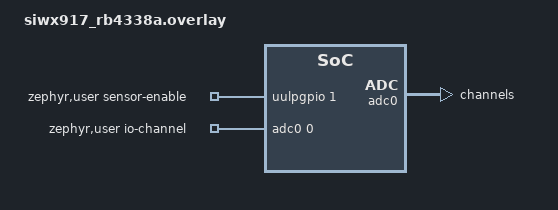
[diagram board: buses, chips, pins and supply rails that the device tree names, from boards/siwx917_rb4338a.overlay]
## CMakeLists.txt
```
# SPDX-License-Identifier: Apache-2.0

cmake_minimum_required(VERSION 3.20.0)

find_package(Zephyr REQUIRED HINTS $ENV{ZEPHYR_BASE})
project(ghanode)

target_sources(app PRIVATE
  src/main.c
  src/sensors.c
  src/wifi.c
  src/mqtt_link.c
  src/reading.c
  src/payload.c
  src/lux.c
  src/recovery.c
  src/sntp_sync.c
  src/timesync.c
)

# secret.h (gitignored) lives next to this file.
target_include_directories(app PRIVATE ${CMAKE_CURRENT_SOURCE_DIR})

if(CONFIG_GHANODE_MQTT_TLS)
  set(gen_dir ${ZEPHYR_BINARY_DIR}/include/generated)
  generate_inc_file_for_target(app ${CMAKE_CURRENT_SOURCE_DIR}/certs/isrg_root_x1.pem
                               ${gen_dir}/isrg_root_x1.pem.inc)
endif()
```

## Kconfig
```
# SPDX-License-Identifier: Apache-2.0

mainmenu "ghanode SiWx917 sensor node"

menu "ghanode"

config GHANODE_MQTT_TLS
	bool "MQTT over TLS"
	default y
	depends on MQTT_LIB_TLS
	help
	  The broker must present a certificate for SECRET_MQTT_TLS_HOSTNAME
	  that chains to ISRG Root X1 (certs/isrg_root_x1.pem). The node does
	  not keep a wall clock for mbed TLS, so certificate dates are not
	  checked. Disable for plain MQTT.

config GHANODE_MQTT_BROKER_PORT
	int "MQTT broker port"
	default 8883 if GHANODE_MQTT_TLS
	default 1883

config GHANODE_MQTT_TOPIC
	string "MQTT topic readings are published to"
	default "ghanode/sensor"

config GHANODE_SAMPLE_INTERVAL_MS
	int "Sample period in milliseconds"
	default 20000

config GHANODE_READING_QUEUE_LEN
	int "Readings kept while the broker cannot be reached"
	range 1 1024
	default 30
	help
	  Bridges short outages such as a Wi-Fi handover. 30 readings at the
	  default 20 s period cover ten minutes, the same as the recovery
	  ladder's grace period before an MCU reset, which empties the queue.
	  When the queue is full the oldest reading is dropped.

config GHANODE_SNTP_RESYNC_S
	int "Seconds between SNTP queries once synced"
	default 3600

config GHANODE_SNTP_RETRY_S
	int "Seconds before retrying a failed SNTP query"
	default 60

config GHANODE_WIFI_COUNTRY
	string "Wi-Fi regulatory country code (ISO 3166-1 alpha-2)"
	default "DK"
	help
	  The NWP's default region is US, which only scans channels 1-11. Any
	  EU country code selects the EU region and enables channels 12 and 13.

endmenu

source "Kconfig.zephyr"
```

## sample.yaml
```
sample:
  name: ghanode
  description: SiWx917 sensor node publishing Si7021 and light readings over MQTT
common:
  tags:
    - net
    - wifi
    - mqtt
    - sensors
  harness: net
tests:
  ghanode.siwx917:
    platform_allow:
      - siwx917_rb4338a
    integration_platforms:
      - siwx917_rb4338a
```

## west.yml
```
# Workspace for CI, or for a fresh checkout:
#   west init -l ghanode_ze_si917 && west update
# An existing workspace with the same SDK can build this repo without it.

manifest:
  self:
    path: ghanode_ze_si917

  remotes:
    - name: silabs
      url-base: https://github.com/siliconlabssoftware

  projects:
    # Simplicity SDK for Zephyr; v2026.6.0 is based on Zephyr 4.4.1.
    - name: zephyr-silabs
      remote: silabs
      revision: v2026.6.0
      import: true
```

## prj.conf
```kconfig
# Networking: Zephyr's native IPv4/TCP stack on top of the SiWx91x Wi-Fi driver
CONFIG_NETWORKING=y
CONFIG_NET_IPV4=y
CONFIG_NET_IPV6=n
CONFIG_NET_TCP=y
CONFIG_NET_UDP=y
CONFIG_NET_SOCKETS=y
CONFIG_NET_DHCPV4=y
CONFIG_NET_MGMT=y
CONFIG_NET_MGMT_EVENT=y
CONFIG_NET_MGMT_EVENT_INFO=y
CONFIG_NET_HOSTNAME_ENABLE=y
CONFIG_NET_HOSTNAME_DYNAMIC=y
# A TCP connect to a host that is down fails after this; a closed port fails at once.
CONFIG_NET_SOCKETS_CONNECT_TIMEOUT=10000

CONFIG_NET_PKT_RX_COUNT=16
CONFIG_NET_PKT_TX_COUNT=16
CONFIG_NET_BUF_RX_COUNT=32
CONFIG_NET_BUF_TX_COUNT=32
CONFIG_NET_MAX_CONTEXTS=6

CONFIG_WIFI=y
CONFIG_WIFI_LOG_LEVEL_WRN=y

# SNTP timestamps; the DNS server comes from DHCP.
CONFIG_SNTP=y
CONFIG_DNS_RESOLVER=y

CONFIG_MQTT_LIB=y
CONFIG_MQTT_KEEPALIVE=60
CONFIG_MQTT_CLEAN_SESSION=y

# MQTT over TLS (CONFIG_GHANODE_MQTT_TLS): TLS 1.2 with the broker's RSA
# certificate. The broker's chain arrives in one record of up to 16 KB; the
# node only sends small ones.
CONFIG_MQTT_LIB_TLS=y
CONFIG_NET_SOCKETS_SOCKOPT_TLS=y
CONFIG_MBEDTLS=y
CONFIG_MBEDTLS_CIPHERSUITE_TLS_ECDHE_RSA_WITH_AES_128_GCM_SHA256=y
CONFIG_MBEDTLS_CIPHERSUITE_TLS_ECDHE_RSA_WITH_AES_256_GCM_SHA384=y
CONFIG_MBEDTLS_PEM_PARSE_C=y
CONFIG_MBEDTLS_SSL_SERVER_NAME_INDICATION=y
CONFIG_MBEDTLS_ENABLE_HEAP=y
CONFIG_MBEDTLS_HEAP_SIZE=65000
CONFIG_MBEDTLS_SSL_IN_CONTENT_LEN=16384
CONFIG_MBEDTLS_SSL_OUT_CONTENT_LEN=4096
# The software handshake takes about 9 s on the board, against a 10 s default.
# The p256-m driver (CONFIG_MBEDTLS_PSA_P256M_DRIVER_ENABLED) failed the ECDHE
# step with -0x7f80 here.
CONFIG_NET_SOCKETS_TLS_CONNECT_TIMEOUT=30000
# Logs the Mbed TLS error code when a handshake fails.
CONFIG_NET_LOG=y
CONFIG_NET_SOCKETS_LOG_LEVEL_ERR=y

# Peripherals
CONFIG_GPIO=y
CONFIG_I2C=y
CONFIG_SENSOR=y
CONFIG_ADC=y

# Kernel
CONFIG_EVENTS=y
CONFIG_REBOOT=y
CONFIG_MAIN_STACK_SIZE=2048
CONFIG_THREAD_NAME=y
CONFIG_THREAD_STACK_INFO=y
CONFIG_INIT_STACKS=y

# Logging and float formatting (log messages and the JSON payload)
CONFIG_LOG=y
CONFIG_CBPRINTF_FP_SUPPORT=y
CONFIG_PICOLIBC_IO_FLOAT=y
```

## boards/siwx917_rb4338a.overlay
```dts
/*
 * BRD4338A on a BRD4002A mainboard.
 *
 * SPDX-License-Identifier: Apache-2.0
 */

/ {
	zephyr,user {
		/* GL5528 photoresistor: GPIO_25 to GND, 4.7 kOhm pull-up to 3.3 V */
		io-channels = <&adc0 0>;
		/* Powers the Si7021 on the mainboard (UULP_VBAT_GPIO_1) */
		sensor-enable-gpios = <&uulpgpio 1 GPIO_ACTIVE_HIGH>;
	};
};

&adc0_default {
	group {
		pinmux = <ADC_TOPGPIO_HP25>;
	};
};

&adc0 {
	channel@0 {
		zephyr,input-positive = <SIWX91X_ADC_INPUT_HP25>;
	};
};
```

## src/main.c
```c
/*
 * ghanode: SiWx917 sensor node publishing Si7021 and light readings over MQTT.
 *
 * SPDX-License-Identifier: Apache-2.0
 */

#include <zephyr/fatal.h>
#include <zephyr/kernel.h>
#include <zephyr/logging/log.h>
#include <zephyr/logging/log_ctrl.h>

#include "app.h"
#include "mqtt_link.h"
#include "sensors.h"
#include "wifi.h"

LOG_MODULE_REGISTER(main, LOG_LEVEL_INF);

/* The TLS handshake, certificate check included, runs on the network thread's stack. */
#if defined(CONFIG_GHANODE_MQTT_TLS)
#define NET_STACK_SIZE    8192
#else
#define NET_STACK_SIZE    4096
#endif
#define SENSOR_STACK_SIZE 2048
/* The sensor thread outranks the network thread so a slow reconnect never delays a sample. */
#define SENSOR_PRIORITY   K_PRIO_PREEMPT(10)
#define NET_PRIORITY      K_PRIO_PREEMPT(11)

/* Stack high-water marks are logged after the first sample, then hourly. */
#define STACK_REPORT_EVERY_N_SAMPLES (3600000U / CONFIG_GHANODE_SAMPLE_INTERVAL_MS)

/* Holds readings through a broker or Wi-Fi outage. When full, the oldest is dropped. */
K_MSGQ_DEFINE(reading_queue, sizeof(struct sensor_reading), CONFIG_GHANODE_READING_QUEUE_LEN, 8);
K_EVENT_DEFINE(net_events);

/* Written by the fatal error handler for a debugger to read. */
const char *volatile fatal_thread_name;

static void sensor_thread_fn(void *p1, void *p2, void *p3);
static void net_thread_fn(void *p1, void *p2, void *p3);

/* Started from main() once the sensors are up. */
K_THREAD_DEFINE(sensor_tid, SENSOR_STACK_SIZE, sensor_thread_fn, NULL, NULL, NULL,
		SENSOR_PRIORITY, 0, SYS_FOREVER_MS);
K_THREAD_DEFINE(net_tid, NET_STACK_SIZE, net_thread_fn, NULL, NULL, NULL, NET_PRIORITY, 0,
		SYS_FOREVER_MS);

/* Only the sensor thread puts. */
static void enqueue_reading(const struct sensor_reading *reading)
{
	if (reading_queue_put(&reading_queue, reading)) {
		LOG_INF("Reading queue full, dropped the oldest reading");
	}
}

static void log_stack_high_water(void)
{
	size_t net_unused = 0;
	size_t sensor_unused = 0;

	(void)k_thread_stack_space_get(net_tid, &net_unused);
	(void)k_thread_stack_space_get(sensor_tid, &sensor_unused);
	LOG_INF("Stack unused at high-water: net %zu of %u B, sensor %zu of %u B", net_unused,
		NET_STACK_SIZE, sensor_unused, SENSOR_STACK_SIZE);
}

/*
 * Producer: samples on a fixed period and never touches the network, so
 * readings keep coming while Wi-Fi or the broker is down.
 */
static void sensor_thread_fn(void *p1, void *p2, void *p3)
{
	int64_t next_wake = k_uptime_get();
	uint32_t samples = 0;

	ARG_UNUSED(p1);
	ARG_UNUSED(p2);
	ARG_UNUSED(p3);

	while (true) {
		struct sensor_reading reading = {.uptime_ms = k_uptime_get()};
		float volts = 0.0f;
		int ret;

		ret = si7021_read(&reading.temperature_c, &reading.humidity_pct);
		if (ret == 0) {
			LOG_INF("Si7021: %.2f C, %.2f %%RH", (double)reading.temperature_c,
				(double)reading.humidity_pct);

			ret = light_read(&volts, &reading.light_lux);
			if (ret == 0) {
				LOG_INF("Light on GPIO_25: %.3f V, %d lux", (double)volts,
					reading.light_lux);
			} else {
				LOG_ERR("Light: ADC read failed: %d", ret);
			}
			enqueue_reading(&reading);
		} else {
			/*
			 * A failed measurement would leave 0 C / 0 %RH, which looks
			 * like a real reading.
			 */
			LOG_ERR("Si7021: measurement failed: %d, reading skipped", ret);
		}

		if ((samples % STACK_REPORT_EVERY_N_SAMPLES) == 0U) {
			log_stack_high_water();
		}
		samples++;

		/* An absolute wake-up keeps the period fixed however long the reads took. */
		next_wake += CONFIG_GHANODE_SAMPLE_INTERVAL_MS;
		k_sleep(K_TIMEOUT_ABS_MS(next_wake));
	}
}

static void net_thread_fn(void *p1, void *p2, void *p3)
{
	ARG_UNUSED(p1);
	ARG_UNUSED(p2);
	ARG_UNUSED(p3);

	network_loop();
}

/*
 * Stack overflows (MPU guard) and other fatal errors end up here. Memory may
 * already be corrupt, so only record the thread for a debugger and stop.
 */
void k_sys_fatal_error_handler(unsigned int reason, const struct arch_esf *esf)
{
	ARG_UNUSED(esf);

	fatal_thread_name = k_thread_name_get(k_current_get());
	LOG_PANIC();
	LOG_ERR("Fatal error %u in thread %s, halting", reason,
		fatal_thread_name != NULL ? fatal_thread_name : "?");

	(void)arch_irq_lock();
	for (;;) {
	}
}

int main(void)
{
	int ret;

	/* The NWP has already booted (POST_KERNEL) before any ULP peripheral is touched here. */
	LOG_INF("ghanode starting");

	ret = sensors_init();
	if (ret < 0) {
		LOG_ERR("Sensor bring-up failed: %d", ret);
		return 0;
	}

	ret = wifi_init();
	if (ret < 0) {
		LOG_ERR("Wi-Fi init failed: %d", ret);
		return 0;
	}

	k_thread_name_set(sensor_tid, "sensor");
	k_thread_name_set(net_tid, "net");
	k_thread_start(sensor_tid);
	k_thread_start(net_tid);
	return 0;
}
```

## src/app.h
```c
/*
 * SPDX-License-Identifier: Apache-2.0
 */

#ifndef GHANODE_APP_H_
#define GHANODE_APP_H_

#include <zephyr/kernel.h>

#include "reading.h"

/* Filled by the sensor thread, drained by the network thread. */
extern struct k_msgq reading_queue;

/* net_events bits. Set from net_mgmt callbacks and the recovery path. */
#define NET_EVT_WIFI_DOWN BIT(0)

extern struct k_event net_events;

#endif /* GHANODE_APP_H_ */
```

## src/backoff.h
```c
/*
 * SPDX-License-Identifier: Apache-2.0
 */

#ifndef GHANODE_BACKOFF_H_
#define GHANODE_BACKOFF_H_

#include <stdint.h>

static inline uint32_t next_retry_delay(uint32_t delay_ms, uint32_t max_ms)
{
	return (delay_ms * 2U > max_ms) ? max_ms : delay_ms * 2U;
}

#endif /* GHANODE_BACKOFF_H_ */
```

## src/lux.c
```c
/*
 * SPDX-License-Identifier: Apache-2.0
 */

#include <math.h>

#include "lux.h"

#define ADC_VREF_VOLTS 3.3f

/*
 * GL5528 LDR from GPIO_25 to GND, 4.7 kOhm pull-up to the ADC reference:
 * V = VREF * R_ldr / (R_ldr + R_pullup).
 */
#define LDR_PULLUP_OHMS 4700.0f
/*
 * GL5528 datasheet: 10-20 kOhm at 10 lux, gamma 0.7 (10 to 100 lux). The reading
 * is used against a 2000 lux threshold; part-to-part spread moves that point to
 * 1300-3600 lux, so set R10 from a lux meter reading near 2000 lux.
 */
#define LDR_R10_OHMS 15000.0f
#define LDR_GAMMA    0.7f

/* LDR power law: R = R10 * (lux / 10)^-gamma, inverted for lux. */
int ldr_volts_to_lux(float volts)
{
	/* A full-scale reading means an open LDR or total darkness. */
	if (volts >= ADC_VREF_VOLTS * 0.999f) {
		return 0;
	}
	if (volts <= 0.0f) {
		return LIGHT_LUX_MAX;
	}

	const float r_ldr = LDR_PULLUP_OHMS * volts / (ADC_VREF_VOLTS - volts);
	const float lux = 10.0f * powf(LDR_R10_OHMS / r_ldr, 1.0f / LDR_GAMMA);

	if (lux >= (float)LIGHT_LUX_MAX) {
		return LIGHT_LUX_MAX;
	}
	return (int)(lux + 0.5f);
}
```

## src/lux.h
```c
/*
 * SPDX-License-Identifier: Apache-2.0
 */

#ifndef GHANODE_LUX_H_
#define GHANODE_LUX_H_

#define LIGHT_LUX_MAX 100000

/*
 * Converts the voltage across the GL5528 LDR (4.7 kOhm pull-up to the 3.3 V
 * ADC reference) to lux. Full scale (open LDR or darkness) gives 0; the
 * result is capped at LIGHT_LUX_MAX.
 */
int ldr_volts_to_lux(float volts);

#endif /* GHANODE_LUX_H_ */
```

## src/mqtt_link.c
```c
/*
 * MQTT session, publishing and recovery. Everything here runs on the network
 * thread; the MQTT library calls mqtt_evt_handler() from mqtt_input() on the
 * same thread, so session state needs no locking.
 *
 * SPDX-License-Identifier: Apache-2.0
 */

#include <zephyr/kernel.h>
#include <zephyr/logging/log.h>
#include <zephyr/logging/log_ctrl.h>
#include <zephyr/net/mqtt.h>
#include <zephyr/net/net_ip.h>
#include <zephyr/net/socket.h>
#include <zephyr/net/tls_credentials.h>
#include <zephyr/sys/reboot.h>

#include "app.h"
#include "backoff.h"
#include "mqtt_link.h"
#include "payload.h"
#include "recovery.h"
#include "secrets.h"
#include "sntp_sync.h"
#include "wifi.h"

LOG_MODULE_REGISTER(mqtt_link, LOG_LEVEL_INF);

/* QoS 1, so a reading is only treated as delivered once the broker acknowledges
 * it. One that is not is sent again in the next session, so a subscriber can
 * see a reading twice, with the same Sensor ID and timestamp.
 */
#define PUBLISH_QOS MQTT_QOS_1_AT_LEAST_ONCE

/* "AABBCCDDEEFF" + NUL */
#define SENSOR_ID_LEN     13
#define MQTT_JSON_MAX_LEN 208
#define MQTT_BUF_LEN      256

#define MQTT_CONNACK_WAIT_MS      10000
#define MQTT_PUBLISH_WAIT_MS      10000
#define MQTT_PUBLISH_REJECT_LIMIT 3
#define MQTT_PUBLISH_RETRY_MS     1000
#define MQTT_RETRY_DELAY_MIN_MS   5000
#define MQTT_RETRY_DELAY_MAX_MS   60000
/* How often the loop looks at the reading queue and the Wi-Fi state. */
#define POLL_SLICE_MS             500

static uint8_t rx_buf[MQTT_BUF_LEN];
static uint8_t tx_buf[MQTT_BUF_LEN];
static char payload[MQTT_JSON_MAX_LEN];
static char sensor_id[SENSOR_ID_LEN] = "000000000000";

/* Taken from the queue but not yet acknowledged. Kept across sessions. */
static struct sensor_reading pending;
static bool has_pending;

static struct mqtt_client client;
static struct net_sockaddr_storage broker;
static struct mqtt_utf8 username = MQTT_UTF8_LITERAL(SECRET_MQTT_USERNAME);
static struct mqtt_utf8 password = MQTT_UTF8_LITERAL(SECRET_MQTT_PASSWORD);

#if defined(CONFIG_GHANODE_MQTT_TLS)
#define CA_CERT_TAG 1

/* mbed TLS parses PEM only with the terminating NUL counted in the length. */
static const char ca_cert[] = {
#include "isrg_root_x1.pem.inc"
	'\0'
};
static const sec_tag_t sec_tags[] = {CA_CERT_TAG};
#endif

/* Session state, written by mqtt_evt_handler(). */
static bool connack_received;
static bool mqtt_connected;
static uint16_t inflight_id;
static bool puback_received;

static void mqtt_evt_handler(struct mqtt_client *const c, const struct mqtt_evt *evt)
{
	ARG_UNUSED(c);

	switch (evt->type) {
	case MQTT_EVT_CONNACK:
		connack_received = true;
		mqtt_connected = (evt->result == 0);
		if (mqtt_connected) {
			LOG_INF("Connected to MQTT broker");
		} else {
			LOG_ERR("MQTT broker refused the connection: %d", evt->result);
		}
		break;
	case MQTT_EVT_DISCONNECT:
		LOG_INF("Disconnected from MQTT broker: %d", evt->result);
		mqtt_connected = false;
		break;
	case MQTT_EVT_PUBACK:
		if ((evt->result == 0) && (evt->param.puback.message_id == inflight_id)) {
			puback_received = true;
		}
		break;
	default:
		break;
	}
}

static void mqtt_setup(void)
{
	struct net_sockaddr_in *broker4 = (struct net_sockaddr_in *)&broker;

	broker4->sin_family = NET_AF_INET;
	broker4->sin_port = net_htons(CONFIG_GHANODE_MQTT_BROKER_PORT);
	if (net_addr_pton(NET_AF_INET, SECRET_MQTT_BROKER_ADDR, &broker4->sin_addr) < 0) {
		LOG_ERR("Bad broker address %s", SECRET_MQTT_BROKER_ADDR);
	}

#if defined(CONFIG_GHANODE_MQTT_TLS)
	int ret = tls_credential_add(CA_CERT_TAG, TLS_CREDENTIAL_CA_CERTIFICATE, ca_cert,
				     sizeof(ca_cert));

	if (ret < 0) {
		LOG_ERR("Failed to add the CA certificate: %d", ret);
	}
#endif

	/* The broker drops a session when another client connects with the same ID. */
	wifi_mac_string(sensor_id, sizeof(sensor_id));
	LOG_INF("STA mac=%s (sensor id), broker %s:%d%s", sensor_id, SECRET_MQTT_BROKER_ADDR,
		CONFIG_GHANODE_MQTT_BROKER_PORT,
		IS_ENABLED(CONFIG_GHANODE_MQTT_TLS) ? " over TLS as " SECRET_MQTT_TLS_HOSTNAME
						    : "");
}

static int poll_socket(int timeout_ms)
{
	struct zsock_pollfd fds = {
#if defined(CONFIG_GHANODE_MQTT_TLS)
		.fd = client.transport.tls.sock,
#else
		.fd = client.transport.tcp.sock,
#endif
		.events = ZSOCK_POLLIN,
	};

	return zsock_poll(&fds, 1, timeout_ms);
}

static bool wifi_down(void)
{
	return k_event_test(&net_events, NET_EVT_WIFI_DOWN) != 0;
}

/*
 * Each connect opens a new socket on a fresh ephemeral port, so a reconnect
 * never collides with a session the broker still holds from before a drop.
 */
static int mqtt_connect_and_wait(void)
{
	int64_t deadline;
	int ret;

	mqtt_client_init(&client);
	client.broker = &broker;
	client.evt_cb = mqtt_evt_handler;
	client.client_id.utf8 = (const uint8_t *)sensor_id;
	client.client_id.size = SENSOR_ID_LEN - 1;
	client.user_name = &username;
	client.password = &password;
	client.protocol_version = MQTT_VERSION_3_1_1;
	client.rx_buf = rx_buf;
	client.rx_buf_size = sizeof(rx_buf);
	client.tx_buf = tx_buf;
	client.tx_buf_size = sizeof(tx_buf);
#if defined(CONFIG_GHANODE_MQTT_TLS)
	/* The broker is dialled by address, so the certificate is matched to this name. */
	client.transport.type = MQTT_TRANSPORT_SECURE;
	client.transport.tls.config.peer_verify = TLS_PEER_VERIFY_REQUIRED;
	client.transport.tls.config.sec_tag_list = sec_tags;
	client.transport.tls.config.sec_tag_count = ARRAY_SIZE(sec_tags);
	client.transport.tls.config.hostname = SECRET_MQTT_TLS_HOSTNAME;
#else
	client.transport.type = MQTT_TRANSPORT_NON_SECURE;
#endif

	connack_received = false;
	mqtt_connected = false;

	ret = mqtt_connect(&client);
	if (ret < 0) {
		LOG_ERR("Failed to connect to MQTT broker: %d", ret);
		return ret;
	}

	deadline = k_uptime_get() + MQTT_CONNACK_WAIT_MS;
	while (!connack_received) {
		const int64_t remaining = deadline - k_uptime_get();

		if (remaining <= 0) {
			LOG_ERR("No CONNACK within %u ms", MQTT_CONNACK_WAIT_MS);
			(void)mqtt_abort(&client);
			return -ETIMEDOUT;
		}
		if (wifi_down()) {
			(void)mqtt_abort(&client);
			return -ENETDOWN;
		}
		if (poll_socket(MIN(remaining, POLL_SLICE_MS)) > 0) {
			ret = mqtt_input(&client);
			if (ret < 0) {
				return ret;
			}
		}
	}

	if (!mqtt_connected) {
		(void)mqtt_abort(&client);
		return -ECONNREFUSED;
	}
	return 0;
}

/*
 * Without a time sync a subscriber can only time a reading on arrival, so only
 * a fresh one may go out. An older one would get the wrong time.
 */
static bool too_old_to_send_unstamped(const struct sensor_reading *reading)
{
	return !sntp_synced() &&
	       ((k_uptime_get() - reading->uptime_ms) > CONFIG_GHANODE_SAMPLE_INTERVAL_MS);
}

static int publish_reading(const struct sensor_reading *reading)
{
	static uint16_t next_id;
	struct mqtt_publish_param param = {0};
	int64_t epoch_ms;
	const bool stamped = sntp_uptime_to_epoch_ms(reading->uptime_ms, &epoch_ms);
	const int n = payload_format(payload, sizeof(payload), sensor_id, reading,
				     stamped ? &epoch_ms : NULL);

	if (n < 0) {
		LOG_ERR("MQTT JSON format failed");
		return n;
	}

	/* Message ID 0 is reserved. */
	next_id = (next_id == UINT16_MAX) ? 1 : next_id + 1;
	inflight_id = next_id;
	puback_received = false;

	param.message.topic.topic.utf8 = (const uint8_t *)CONFIG_GHANODE_MQTT_TOPIC;
	param.message.topic.topic.size = sizeof(CONFIG_GHANODE_MQTT_TOPIC) - 1;
	param.message.topic.qos = PUBLISH_QOS;
	param.message.payload.data = (uint8_t *)payload;
	param.message.payload.len = n;
	param.message_id = inflight_id;

	int ret = mqtt_publish(&client, &param);

	if (ret == 0) {
		LOG_INF("MQTT publish: %s", payload);
	}
	return ret;
}

/*
 * Publishes until the session ends. Returns 0 when the broker or Wi-Fi reports
 * a disconnect, and -EPIPE when the session is dead without any disconnect
 * event. *published is set once the broker acknowledges a reading.
 */
static int publish_until_disconnected(bool *published)
{
	bool in_flight = false;
	int64_t ack_deadline = 0;
	int64_t retry_at = 0;
	uint32_t rejections = 0;
	int ret;

	while (true) {
		if (wifi_down()) {
			(void)mqtt_abort(&client);
			return 0;
		}
		if (!mqtt_connected) {
			return 0;
		}

		if (!in_flight) {
			sntp_sync_if_due();
		}

		if (!has_pending && (k_msgq_get(&reading_queue, &pending, K_NO_WAIT) == 0)) {
			has_pending = true;
		}

		if (has_pending && !in_flight && too_old_to_send_unstamped(&pending)) {
			LOG_INF("No SNTP time, dropped a reading taken %lld s ago",
				(k_uptime_get() - pending.uptime_ms) / 1000);
			has_pending = false;
			continue;
		}

		if (has_pending && !in_flight && (k_uptime_get() >= retry_at)) {
			ret = publish_reading(&pending);
			if (ret == 0) {
				in_flight = true;
				ack_deadline = k_uptime_get() + MQTT_PUBLISH_WAIT_MS;
			} else if ((ret == -EMSGSIZE) || (ret == -EINVAL)) {
				has_pending = false;
			} else if (!mqtt_connected) {
				return 0;
			} else {
				rejections++;
				LOG_ERR("MQTT publish rejected: %d (%u in a row)", ret, rejections);
				if (rejections >= MQTT_PUBLISH_REJECT_LIMIT) {
					(void)mqtt_abort(&client);
					return -EPIPE;
				}
				retry_at = k_uptime_get() + MQTT_PUBLISH_RETRY_MS;
			}
		}

		if (poll_socket(POLL_SLICE_MS) > 0) {
			ret = mqtt_input(&client);
			if (ret < 0) {
				LOG_ERR("MQTT input failed: %d", ret);
				return 0;
			}
		}

		ret = mqtt_live(&client);
		if ((ret < 0) && (ret != -EAGAIN)) {
			LOG_ERR("MQTT keep-alive failed: %d", ret);
			(void)mqtt_abort(&client);
			return 0;
		}

		/* mqtt_live() sends a PINGREQ each keep-alive period; one unanswered is tolerated. */
		if (client.unacked_ping > 1) {
			LOG_ERR("No PINGRESP for a whole keep-alive period");
			(void)mqtt_abort(&client);
			return -EPIPE;
		}

		if (in_flight && puback_received) {
			in_flight = false;
			has_pending = false;
			*published = true;
			rejections = 0;
		} else if (in_flight && (k_uptime_get() >= ack_deadline)) {
			LOG_ERR("MQTT publish not acknowledged in %u ms", MQTT_PUBLISH_WAIT_MS);
			(void)mqtt_abort(&client);
			return -EPIPE;
		}
	}
}

static void apply_recovery(enum recovery_action action, const char *reason)
{
	switch (action) {
	case RECOVERY_RESTART_WIFI:
		LOG_ERR("%s, restarting Wi-Fi", reason);
		k_event_post(&net_events, NET_EVT_WIFI_DOWN);
		break;
	case RECOVERY_RESET_MCU:
		LOG_ERR("%s after a Wi-Fi restart and nothing published for %u min, "
			"resetting the MCU",
			reason, RECOVERY_RESET_GRACE_MS / 60000U);
		LOG_PANIC();
		sys_reboot(SYS_REBOOT_COLD);
		break;
	default:
		break;
	}
}

void network_loop(void)
{
	struct recovery recovery;
	uint32_t retry_delay_ms = MQTT_RETRY_DELAY_MIN_MS;
	int ret;

	recovery_init(&recovery, k_uptime_get());

	wifi_join();
	wifi_log_diagnostics();
	mqtt_setup();

	while (true) {
		if (wifi_down()) {
			LOG_ERR("Wi-Fi down, rejoining");
			wifi_restart();
			k_event_clear(&net_events, NET_EVT_WIFI_DOWN);
			wifi_log_diagnostics();
			recovery_wifi_rejoined(&recovery);
		}

		sntp_sync_if_due();

		ret = mqtt_connect_and_wait();
		if (ret == 0) {
			bool published = false;

			retry_delay_ms = MQTT_RETRY_DELAY_MIN_MS;
			recovery_connected(&recovery);
			/*
			 * Without a sync the publish loop drops every queued reading
			 * older than one sample period, so a pending retry must not
			 * wait out its delay now that the network is back.
			 */
			sntp_sync_if_unsynced();
			ret = publish_until_disconnected(&published);
			apply_recovery(recovery_session_ended(&recovery, published, ret < 0,
							      k_uptime_get()),
				       "MQTT session dead without a disconnect");
			continue;
		}

		if (ret == -ENETDOWN) {
			continue;
		}

		apply_recovery(recovery_connect_failed(&recovery, k_uptime_get()),
			       "MQTT connect keeps failing");
		LOG_ERR("MQTT not connected, retrying in %u s", retry_delay_ms / 1000U);
		/* Wakes early if Wi-Fi is lost, so the rejoin is not held up by the backoff. */
		(void)k_event_wait(&net_events, NET_EVT_WIFI_DOWN, false, K_MSEC(retry_delay_ms));
		retry_delay_ms = next_retry_delay(retry_delay_ms, MQTT_RETRY_DELAY_MAX_MS);
	}
}
```

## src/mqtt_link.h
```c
/*
 * SPDX-License-Identifier: Apache-2.0
 */

#ifndef GHANODE_MQTT_LINK_H_
#define GHANODE_MQTT_LINK_H_

/* Network thread body: Wi-Fi bring-up, then publish the reading queue forever. */
void network_loop(void);

#endif /* GHANODE_MQTT_LINK_H_ */
```

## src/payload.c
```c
/*
 * SPDX-License-Identifier: Apache-2.0
 */

#include <errno.h>
#include <stdio.h>

#include "payload.h"

/* "2026-11-04T12:55:00Z" + NUL */
#define UTC_TEXT_LEN 21
#define SECS_PER_DAY 86400
/* 9999-12-31T23:59:59Z, the last time with a four-digit year. */
#define UTC_MAX_EPOCH_S 253402300799LL

/*
 * Days since 1970-01-01 to a proleptic Gregorian date (Howard Hinnant's
 * civil_from_days), restricted to days >= 0.
 */
static void civil_from_days(int64_t days, int *year, int *month, int *day)
{
	const int64_t z = days + 719468;
	const int64_t era = z / 146097;
	const int64_t doe = z - era * 146097;
	const int64_t yoe = (doe - doe / 1460 + doe / 36524 - doe / 146096) / 365;
	const int64_t doy = doe - (365 * yoe + yoe / 4 - yoe / 100);
	const int64_t mp = (5 * doy + 2) / 153;
	const int64_t m = (mp < 10) ? (mp + 3) : (mp - 9);

	*year = (int)(yoe + era * 400 + ((m <= 2) ? 1 : 0));
	*month = (int)m;
	*day = (int)(doy - (153 * mp + 2) / 5 + 1);
}

static int format_utc(char *buf, size_t len, int64_t epoch_ms)
{
	const int64_t secs = epoch_ms / 1000;
	const int64_t sod = secs % SECS_PER_DAY;
	int year;
	int month;
	int day;
	int n;

	if ((epoch_ms < 0) || (secs > UTC_MAX_EPOCH_S)) {
		return -EINVAL;
	}
	civil_from_days(secs / SECS_PER_DAY, &year, &month, &day);
	n = snprintf(buf, len, "%04d-%02d-%02dT%02d:%02d:%02dZ", year, month, day,
		     (int)(sod / 3600), (int)((sod / 60) % 60), (int)(sod % 60));
	if ((n <= 0) || ((size_t)n >= len)) {
		return -EINVAL;
	}
	return 0;
}

int payload_format(char *buf, size_t len, const char *sensor_id,
		   const struct sensor_reading *reading, const int64_t *epoch_ms)
{
	const double temperature = (double)reading->temperature_c;
	const int humidity = (int)(reading->humidity_pct + 0.5f);
	char utc[UTC_TEXT_LEN];
	int n;

	if (epoch_ms == NULL) {
		n = snprintf(buf, len,
			     "{\"Sensor ID\": \"%s\", \"temperature\":%.1f, \"humidity\": %d, "
			     "\"light\": %d}",
			     sensor_id, temperature, humidity, reading->light_lux);
	} else {
		if (format_utc(utc, sizeof(utc), *epoch_ms) < 0) {
			return -EINVAL;
		}
		n = snprintf(buf, len,
			     "{\"Sensor ID\": \"%s\", \"temperature\":%.1f, \"humidity\": %d, "
			     "\"light\": %d, \"timestamp\": \"%s\"}",
			     sensor_id, temperature, humidity, reading->light_lux, utc);
	}

	if ((n <= 0) || ((size_t)n >= len)) {
		return -EMSGSIZE;
	}
	return n;
}
```

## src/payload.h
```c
/*
 * SPDX-License-Identifier: Apache-2.0
 */

#ifndef GHANODE_PAYLOAD_H_
#define GHANODE_PAYLOAD_H_

#include <stddef.h>
#include <stdint.h>

#include "reading.h"

/*
 * Formats a reading as JSON. Key names and spacing match the payload of the
 * FreeRTOS node. Humidity is rounded to whole %RH.
 * epoch_ms, when not NULL, is the sample time in milliseconds since 1970 and
 * is added as a "timestamp" in UTC, whole seconds.
 * Returns the length written, -EMSGSIZE if it does not fit in len, or
 * -EINVAL for a time that cannot be formatted.
 */
int payload_format(char *buf, size_t len, const char *sensor_id,
		   const struct sensor_reading *reading, const int64_t *epoch_ms);

#endif /* GHANODE_PAYLOAD_H_ */
```

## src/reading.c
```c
/*
 * SPDX-License-Identifier: Apache-2.0
 */

#include "reading.h"

bool reading_queue_put(struct k_msgq *queue, const struct sensor_reading *reading)
{
	struct sensor_reading discarded;
	bool dropped = false;

	while (k_msgq_put(queue, reading, K_NO_WAIT) != 0) {
		if (k_msgq_get(queue, &discarded, K_NO_WAIT) == 0) {
			dropped = true;
		}
	}
	return dropped;
}
```

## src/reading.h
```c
/*
 * SPDX-License-Identifier: Apache-2.0
 */

#ifndef GHANODE_READING_H_
#define GHANODE_READING_H_

#include <stdbool.h>
#include <stdint.h>

#include <zephyr/kernel.h>

struct sensor_reading {
	/* k_uptime_get() when the sample was taken; turned into UTC at publish time. */
	int64_t uptime_ms;
	float temperature_c;
	float humidity_pct;
	int light_lux;
};

/*
 * Puts a reading into the queue. When the queue is full the oldest unpublished
 * reading is dropped to make room. Returns true when that happened. Only one
 * thread may put.
 */
bool reading_queue_put(struct k_msgq *queue, const struct sensor_reading *reading);

#endif /* GHANODE_READING_H_ */
```

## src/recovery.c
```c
/*
 * SPDX-License-Identifier: Apache-2.0
 */

#include "recovery.h"

static enum recovery_action escalate(struct recovery *r, int64_t now_ms)
{
	if (!r->recovered_once) {
		r->recovered_once = true;
		return RECOVERY_RESTART_WIFI;
	}
	if ((now_ms - r->last_ok_ms) < RECOVERY_RESET_GRACE_MS) {
		return RECOVERY_NONE;
	}
	return RECOVERY_RESET_MCU;
}

void recovery_init(struct recovery *r, int64_t now_ms)
{
	r->recovered_once = false;
	r->fails_after_recovery = 0;
	r->last_ok_ms = now_ms;
}

void recovery_wifi_rejoined(struct recovery *r)
{
	/*
	 * A rejoin after a lost link is a recovery too, so connects that keep
	 * failing afterwards still end in a reset once the grace period is over.
	 */
	r->recovered_once = true;
	r->fails_after_recovery = 0;
}

void recovery_connected(struct recovery *r)
{
	r->fails_after_recovery = 0;
}

enum recovery_action recovery_session_ended(struct recovery *r, bool published, bool dead,
					    int64_t now_ms)
{
	if (published) {
		r->recovered_once = false;
		r->last_ok_ms = now_ms;
	}
	return dead ? escalate(r, now_ms) : RECOVERY_NONE;
}

enum recovery_action recovery_connect_failed(struct recovery *r, int64_t now_ms)
{
	/*
	 * A clean failure normally means the broker is down. Right after a
	 * Wi-Fi restart it can also mean the link is wedged.
	 */
	if (r->recovered_once && (++r->fails_after_recovery >= RECOVERY_CONNECT_FAILS)) {
		return escalate(r, now_ms);
	}
	return RECOVERY_NONE;
}
```

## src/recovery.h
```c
/*
 * Recovery ladder: a dead MQTT session first restarts Wi-Fi. If no publish
 * gets through before the next failure, or RECOVERY_CONNECT_FAILS connects in
 * a row fail after a Wi-Fi restart or rejoin, the MCU is reset, but only once
 * RECOVERY_RESET_GRACE_MS have passed without an acknowledged publish. The
 * reading queue is in RAM, so a reset inside that window would throw away the
 * readings it is there to bridge.
 *
 * SPDX-License-Identifier: Apache-2.0
 */

#ifndef GHANODE_RECOVERY_H_
#define GHANODE_RECOVERY_H_

#include <stdbool.h>
#include <stdint.h>

#define RECOVERY_CONNECT_FAILS  3
#define RECOVERY_RESET_GRACE_MS (10 * 60 * 1000)

enum recovery_action {
	RECOVERY_NONE,
	RECOVERY_RESTART_WIFI,
	RECOVERY_RESET_MCU,
};

struct recovery {
	bool recovered_once;
	uint32_t fails_after_recovery;
	/* Uptime of the last acknowledged publish, or of boot. */
	int64_t last_ok_ms;
};

void recovery_init(struct recovery *r, int64_t now_ms);

/* Wi-Fi came back after a loss or a restart. */
void recovery_wifi_rejoined(struct recovery *r);

/* The broker accepted a connect. */
void recovery_connected(struct recovery *r);

/*
 * A session ended. published: the broker acknowledged at least one reading.
 * dead: the session died without a disconnect event.
 */
enum recovery_action recovery_session_ended(struct recovery *r, bool published, bool dead,
					    int64_t now_ms);

/* A connect failed cleanly (refused or timed out), not because Wi-Fi was down. */
enum recovery_action recovery_connect_failed(struct recovery *r, int64_t now_ms);

#endif /* GHANODE_RECOVERY_H_ */
```
